# AUX_TIMER register map
Vendor: Texas Instruments
Peripheral module from a debugger description file (folder CC2650).
Registers are 32-bit, access per field, reset 0x0 unless marked. A register's access mark holds for its fields unless they carry their own. Offsets are as the file gives them; lines under a group give offsets from that group; [hi:lo] are bit positions; {n}, {i} and the like mark numbered series; 'fields as' and 'values as' point back to an identical list; <NAME> marks a mode.

## AUX_TIMER
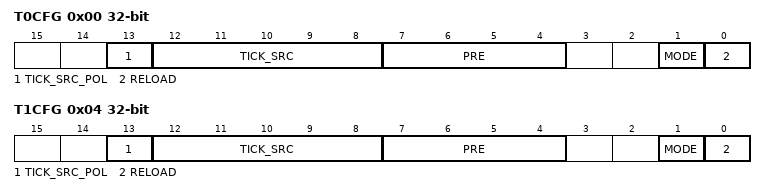
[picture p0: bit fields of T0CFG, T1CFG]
0x00 T0CFG — Timer 0 Configuration
  [13] TICK_SRC_POL rw — Source count polarity for timer 0
    1=FALL (Count on falling edges of TICK_SRC); 0=RISE (Count on rising edges of TICK_SRC)
  [12:8] TICK_SRC rw — Selected tick source for timer 0
    31=ADC_IRQ (Selects ADC_IRQ); 30=MCU_EVENT (Selects MCU_EV); 29=ACLK_REF (Selects ACLK_REF); {v}=AUXIO{v-13} (Selects AUXIO{v-13}) (v=13..28); 12=AON_PROG_WU (Selects AON_PROG_WU); 11=AON_SW (Selects AON_SW); 10=OBSMUX1 (Selects OBSMUX1); 9=OBSMUX0 (Selects OBSMUX0); 8=RTC_4KHZ (Selects RTC_4KHZ); 7=ADC_DONE (Selects ADC_DONE); 6=SMPH_AUTOTAKE_DONE (Selects SMPH_AUTOTAKE_DONE); 5=TIMER1_EV (Selects TIMER1_EV); 3=TDC_DONE (Selects TDC_DONE); 2=AUX_COMPB (Selects AUX_COMPB); 1=AUX_COMPA (Selects AUX_COMPA); 0=RTC_CH2_EV (Selects RTC_CH2_EV)
  [7:4] PRE rw — Prescaler division ratio is 2^PRE
  [1] MODE rw — Timer 0 mode
    1=TICK (Timer 0 counter increments only on edges of the event set by TICK_SRC. The events are divided by the PRE setting.); 0=CLK (Timer 0 increments on every 2^PRE edges of AUX clock)
  [0] RELOAD rw — Timer 0 reload setting
    1=CONT (Timer is automatically restarted when target is reached); 0=MAN (Timer has to be restarted manually)
0x04 T1CFG — Timer 1 Configuration
  [13] TICK_SRC_POL rw — Source count polarity for timer 1
    values as T0CFG.TICK_SRC_POL
  [12:8] TICK_SRC rw — Selected tick source for timer 1
    31=ADC_IRQ (Selects ADC_IRQ); 30=MCU_EVENT (Selects MCU_EV); 29=ACLK_REF (Selects ACLK_REF); {v}=AUXIO{v-13} (Selects AUXIO{v-13}) (v=13..28); 12=AON_PROG_WU (Selects AON_PROG_WU); 11=AON_SW (Selects AON_SW); 10=OBSMUX1 (Selects OBSMUX1); 9=OBSMUX0 (Selects OBSMUX0); 8=RTC_4KHZ (Selects RTC_4KHZ); 7=ADC_DONE (Selects ADC_DONE); 6=SMPH_AUTOTAKE_DONE (Selects SMPH_AUTOTAKE_DONE); 4=TIMER0_EV (Selects TIMER0_EV); 3=TDC_DONE (Selects TDC_DONE); 2=AUX_COMPB (Selects AUX_COMPB); 1=AUX_COMPA (Selects AUX_COMPA); 0=RTC_CH2_EV (Selects RTC_CH2_EV)
  [7:4] PRE rw — Prescaler division ratio is 2^PRE
  [1] MODE rw — Timer 1 mode
    1=TICK (Timer 1 counter increments only on edges of the event set by TICK_SRC. The events are divided by the PRE setting.); 0=CLK (Timer 1 increments on every 2^PRE edges of AUX clock)
  [0] RELOAD rw — Timer 1 reload setting
    values as T0CFG.RELOAD
0x08 T0CTL — Timer 0 Control Run control/status for timer 0
  [0] EN rw — Timer 0 run enable control. The counter restarts when enabling the timer. If T0CFG.RELOAD = 0, the timer is automatically disabled when reaching T0TARGET.VALUE 0: Disable timer 0 1: Enable timer 0
0x0C T0TARGET — Timer 0 Target Target counter value for timer 0
  [15:0] VALUE rw — Timer 0 counts from 0 to VALUE. Then gives an event and restarts if configured to do to so in the T0CFG.RELOAD setting. If VALUE is changed while timer 0 is running so that the count becomes higher than VALUE timer 0 will also restart if configured to do so. If T0CFG.MODE=0,no prescaler is used, and VALUE equals 1, the TIMER0_EV event line will be always set
0x10 T1TARGET — Timer 1 Target Target Counter Value Timer 1
  [7:0] VALUE rw — Timer 1 counts from 0 to VALUE. Then gives an event and restarts if configured to do to so in the T1CFG.RELOAD setting. If VALUE is changed while timer 1 is running so that the count becomes higher than VALUE timer 1 will also restart if configured to do so. If T1CFG.MODE=0,no prescaler is used, and VALUE equals 1, the TIMER1_EV event line will be always set
0x14 T1CTL — Timer 1 Control Run Control/Status For Timer 1
  [0] EN rw — Timer 1 run enable control. The counter restarts when enabling the timer. If T1CFG.RELOAD = 0, the timer is automatically disabled when reaching T1TARGET.VALUE 0: Disable timer 1 1: Enable timer 1
